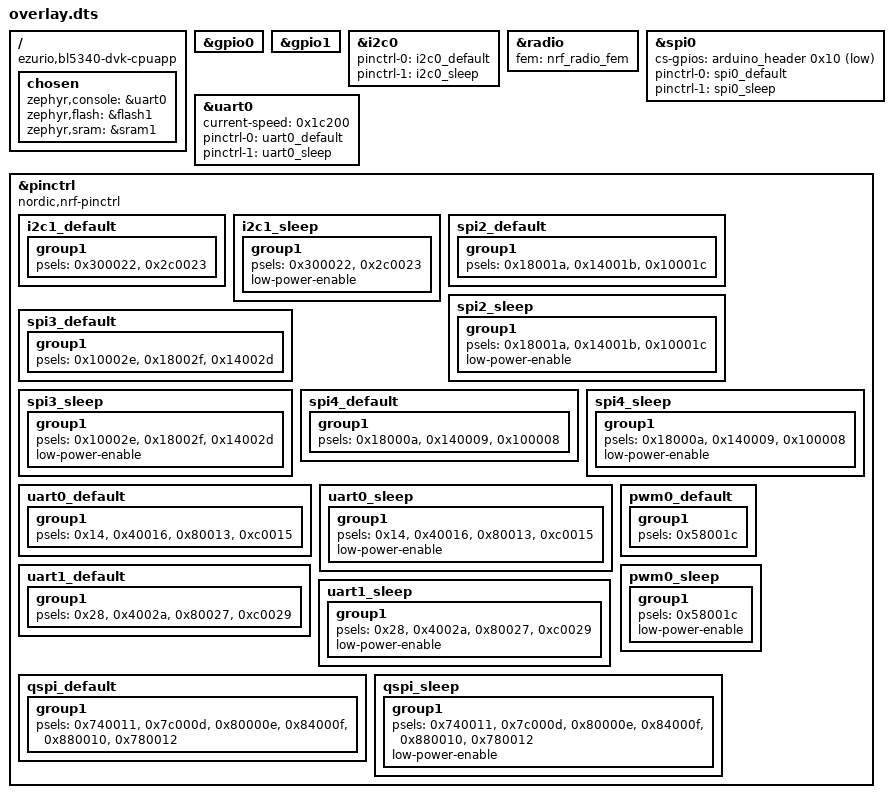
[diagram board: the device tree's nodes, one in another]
/ {
	compatible = "ezurio,bl5340-dvk-cpuapp";
	chosen {
		zephyr,console = &uart0;
		zephyr,flash = &flash1;
		zephyr,sram = &sram1;
	};
};
&gpio0{
	status = "okay";
};
&gpio1{
	status = "okay";
};
&i2c0{
	pinctrl-0 = < &i2c0_default >;
	pinctrl-1 = < &i2c0_sleep >;
	pinctrl-names = "default", "sleep";
};
&radio{
	fem = < &nrf_radio_fem >;
};
&spi0{
	cs-gpios = < &arduino_header 0x10 0x1 >;
	pinctrl-0 = < &spi0_default >;
	pinctrl-1 = < &spi0_sleep >;
	pinctrl-names = "default", "sleep";
};
&uart0{
	status = "okay";
	current-speed = < 0x1c200 >;
	pinctrl-0 = < &uart0_default >;
	pinctrl-1 = < &uart0_sleep >;
	pinctrl-names = "default", "sleep";
};
&pinctrl{
	compatible = "nordic,nrf-pinctrl";
	i2c1_default: i2c1_default {
		group1 {
			psels = < 0x300022 >, < 0x2c0023 >;
		};
	};
	i2c1_sleep: i2c1_sleep {
		group1 {
			psels = < 0x300022 >, < 0x2c0023 >;
			low-power-enable;
		};
	};
	spi2_default: spi2_default {
		group1 {
			psels = < 0x18001a >, < 0x14001b >, < 0x10001c >;
		};
	};
	spi2_sleep: spi2_sleep {
		group1 {
			psels = < 0x18001a >, < 0x14001b >, < 0x10001c >;
			low-power-enable;
		};
	};
	spi3_default: spi3_default {
		group1 {
			psels = < 0x10002e >, < 0x18002f >, < 0x14002d >;
		};
	};
	spi3_sleep: spi3_sleep {
		group1 {
			psels = < 0x10002e >, < 0x18002f >, < 0x14002d >;
			low-power-enable;
		};
	};
	spi4_default: spi4_default {
		group1 {
			psels = < 0x18000a >, < 0x140009 >, < 0x100008 >;
		};
	};
	spi4_sleep: spi4_sleep {
		group1 {
			psels = < 0x18000a >, < 0x140009 >, < 0x100008 >;
			low-power-enable;
		};
	};
	uart0_default: uart0_default {
		group1 {
			psels = < 0x14 >, < 0x40016 >, < 0x80013 >, < 0xc0015 >;
		};
	};
	uart0_sleep: uart0_sleep {
		group1 {
			psels = < 0x14 >, < 0x40016 >, < 0x80013 >, < 0xc0015 >;
			low-power-enable;
		};
	};
	uart1_default: uart1_default {
		group1 {
			psels = < 0x28 >, < 0x4002a >, < 0x80027 >, < 0xc0029 >;
		};
	};
	uart1_sleep: uart1_sleep {
		group1 {
			psels = < 0x28 >, < 0x4002a >, < 0x80027 >, < 0xc0029 >;
			low-power-enable;
		};
	};
	pwm0_default: pwm0_default {
		group1 {
			psels = < 0x58001c >;
		};
	};
	pwm0_sleep: pwm0_sleep {
		group1 {
			psels = < 0x58001c >;
			low-power-enable;
		};
	};
	qspi_default: qspi_default {
		group1 {
			psels = < 0x740011 >, < 0x7c000d >, < 0x80000e >, < 0x84000f >, < 0x880010 >, < 0x780012 >;
		};
	};
	qspi_sleep: qspi_sleep {
		group1 {
			psels = < 0x740011 >, < 0x7c000d >, < 0x80000e >, < 0x84000f >, < 0x880010 >, < 0x780012 >;
			low-power-enable;
		};
	};
};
